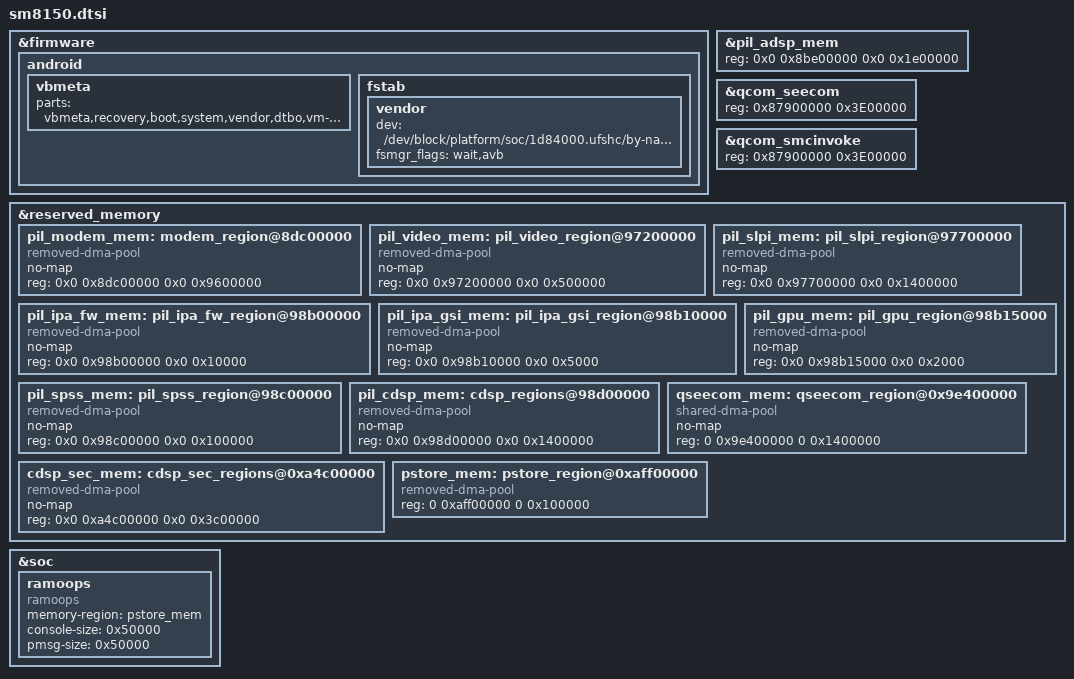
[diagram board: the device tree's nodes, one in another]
&firmware {
     android {
	    vbmeta {
		    parts = "vbmeta,recovery,boot,system,vendor,dtbo,vm-linux";
	    };
	    fstab {
		     vendor {
			    dev = "/dev/block/platform/soc/1d84000.ufshc/by-name/vendor";
			    fsmgr_flags = "wait,avb";
		     };
	    };
     };
};

&pil_adsp_mem{
	reg = <0x0 0x8be00000 0x0 0x1e00000>;
};

&qcom_seecom {
	 reg = <0x87900000 0x3E00000>;
};

&qcom_smcinvoke {
	reg = <0x87900000 0x3E00000>;
};

&reserved_memory {
    /delete-node/ modem_region@8d800000;
    /delete-node/ pil_video_region@96e00000;
    /delete-node/ pil_slpi_region@97300000;
    /delete-node/ pil_ipa_fw_region@98700000;
    /delete-node/ pil_ipa_gsi_region@98710000;
    /delete-node/ pil_gpu_region@98715000;
    /delete-node/ pil_spss_region@98800000;
    /delete-node/ cdsp_regions@98900000;
    
		pil_modem_mem: modem_region@8dc00000 {
                        compatible = "removed-dma-pool";
                        no-map;
                        reg = <0x0 0x8dc00000 0x0 0x9600000>;
                };

                pil_video_mem: pil_video_region@97200000 {
                        compatible = "removed-dma-pool";
                        no-map;
                        reg = <0x0 0x97200000 0x0 0x500000>;
                };

                pil_slpi_mem: pil_slpi_region@97700000 {
                        compatible = "removed-dma-pool";
                        no-map;
                        reg = <0x0 0x97700000 0x0 0x1400000>;
                };

                pil_ipa_fw_mem: pil_ipa_fw_region@98b00000 {
                        compatible = "removed-dma-pool";
                        no-map;
                        reg = <0x0 0x98b00000 0x0 0x10000>;
                };

                pil_ipa_gsi_mem: pil_ipa_gsi_region@98b10000 {
                        compatible = "removed-dma-pool";
                        no-map;
                        reg = <0x0 0x98b10000 0x0 0x5000>;
                };

                pil_gpu_mem: pil_gpu_region@98b15000 {
                        compatible = "removed-dma-pool";
                        no-map;
                        reg = <0x0 0x98b15000 0x0 0x2000>;
                };

                pil_spss_mem: pil_spss_region@98c00000 {
                        compatible = "removed-dma-pool";
                        no-map;
                        reg = <0x0 0x98c00000 0x0 0x100000>;
                };

                pil_cdsp_mem: cdsp_regions@98d00000 {
                        compatible = "removed-dma-pool";
                        no-map;
                        reg = <0x0 0x98d00000 0x0 0x1400000>;
                };

                qseecom_mem: qseecom_region@0x9e400000 {
                        compatible = "shared-dma-pool";
                        no-map;
                        reg = <0 0x9e400000 0 0x1400000>;
                };

                cdsp_sec_mem: cdsp_sec_regions@0xa4c00000 {
                        compatible = "removed-dma-pool";
                        no-map;
                        reg = <0x0 0xa4c00000 0x0 0x3c00000>;
                };

                pstore_mem: pstore_region@0xaff00000 {
                        compatible = "removed-dma-pool";
                        reg = <0 0xaff00000 0 0x100000>;
                };
};

&soc {
	ramoops {
		compatible = "ramoops";
		memory-region = <&pstore_mem>;
		console-size = <0x50000>;
		pmsg-size = <0x50000>;
	};
};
